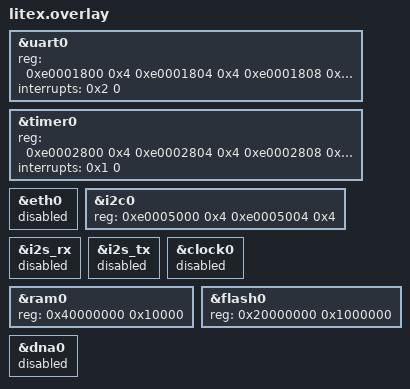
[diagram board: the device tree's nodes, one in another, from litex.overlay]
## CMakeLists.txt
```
set(CONF_FILE prj.conf litex.conf)
set(DTC_OVERLAY_FILE litex.overlay app.overlay)
set(BOARD litex_vexriscv)

cmake_minimum_required(VERSION 3.20.0)
find_package(Zephyr REQUIRED HINTS $ENV{ZEPHYR_BASE})
project(shell_module)

target_sources(app PRIVATE src/main.c)
```

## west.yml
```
# Copyright (c) 2023 tinyVision.ai Inc.
# SPDX-License-Identifier: MIT

manifest:

  remotes:
    - name: zephyrproject-rtos
      url-base: https://github.com/zephyrproject-rtos
    - name: tinyvision-ai-inc
      url-base: https://github.com/tinyvision-ai-inc

  projects:
    - name: zephyr
      remote: zephyrproject-rtos
      revision: main
      import:
        name-allowlist:
          - zephyr
```

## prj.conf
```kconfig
DTC_OVERLAY_FILE=litex.overlay;app.overlay
CONFIG_I2C=y
```

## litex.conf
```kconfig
CONFIG_UART_LITEUART=y
CONFIG_LITEX_TIMER=y
CONFIG_ETH_LITEETH=n
CONFIG_I2C_LITEX=y
CONFIG_I2S_LITEX=n
CONFIG_I2S_LITEX=n
CONFIG_CLOCK_CONTROL_LITEX=n
CONFIG_XIP=y
CONFIG_LITEX_CSR_DATA_WIDTH=32
```

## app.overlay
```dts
&flash0 {
    reg = <0x20100000 0xf00000>;
};
```

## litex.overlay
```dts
&uart0 {
    reg = <0xe0001800 0x4
        0xe0001804 0x4
        0xe0001808 0x4
        0xe000180c 0x4
        0xe0001810 0x4
        0xe0001814 0x4
        0xe0001818 0x4
        0xe000181c 0x4>;
    reg-names = "rxtx",
        "txfull",
        "rxempty",
        "ev_status",
        "ev_pending",
        "ev_enable",
        "txempty",
        "rxfull";
    interrupts = <0x2 0>;
};
&timer0 {
    reg = <0xe0002800 0x4
        0xe0002804 0x4
        0xe0002808 0x4
        0xe000280c 0x4
        0xe0002810 0x4
        0xe0002814 0x4
        0xe0002818 0x4
        0xe000281c 0x4
        0xe0002820 0x4
        0xe0002824 0x8>;
    reg-names = "load",
        "reload",
        "en",
        "update_value",
        "value",
        "ev_status",
        "ev_pending",
        "ev_enable",
        "uptime_latch",
        "uptime_cycles";
    interrupts = <0x1 0>;
};
&eth0 {
    status = "disabled";
};
&i2c0 {
    reg = <0xe0005000 0x4
        0xe0005004 0x4>;
    reg-names = "write",
        "read";
};
&i2s_rx {
    status = "disabled";
};
&i2s_tx {
    status = "disabled";
};
&clock0 {
    status = "disabled";
};
&ram0 {
    reg = <0x40000000 0x10000>;
};
&flash0 {
    reg = <0x20000000 0x1000000>;
};
&dna0 {
    status = "disabled";
};
```

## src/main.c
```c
#include <zephyr/kernel.h>

int main(void) {
    printk("hello world\n");
}
```
